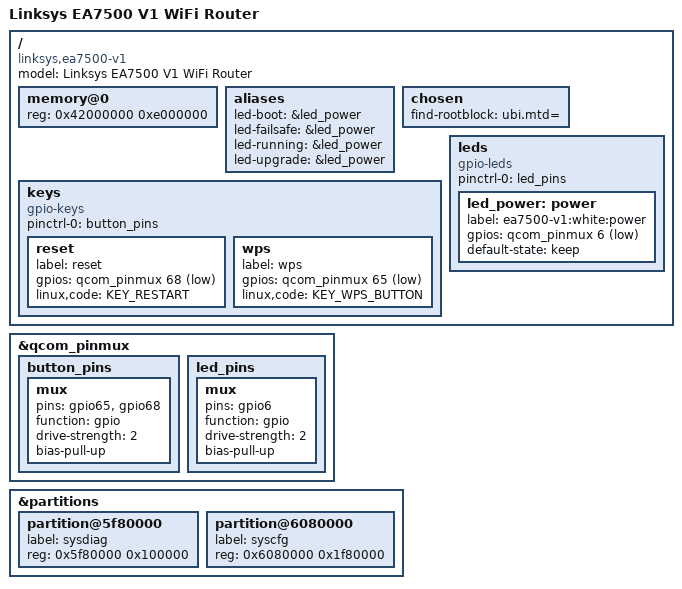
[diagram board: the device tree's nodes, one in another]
// SPDX-License-Identifier: GPL-2.0-or-later OR MIT

#include "qcom-ipq8064-eax500.dtsi"

/ {
	model = "Linksys EA7500 V1 WiFi Router";
	compatible = "linksys,ea7500-v1", "qcom,ipq8064";

	memory@0 {
		reg = <0x42000000 0xe000000>;
		device_type = "memory";
	};

	aliases {
		led-boot = &led_power;
		led-failsafe = &led_power;
		led-running = &led_power;
		led-upgrade = &led_power;
	};

	chosen {
		/* look for root deviceblock nbr in this bootarg */
		find-rootblock = "ubi.mtd=";
	};

	keys {
		compatible = "gpio-keys";
		pinctrl-0 = <&button_pins>;
		pinctrl-names = "default";

		reset {
			label = "reset";
			gpios = <&qcom_pinmux 68 GPIO_ACTIVE_LOW>;
			linux,code = <KEY_RESTART>;
		};

		wps {
			label = "wps";
			gpios = <&qcom_pinmux 65 GPIO_ACTIVE_LOW>;
			linux,code = <KEY_WPS_BUTTON>;
		};
	};

	leds {
		compatible = "gpio-leds";
		pinctrl-0 = <&led_pins>;
		pinctrl-names = "default";

		led_power: power {
			label = "ea7500-v1:white:power";
			gpios = <&qcom_pinmux 6 GPIO_ACTIVE_LOW>;
			default-state = "keep";
		};
	};
};

&qcom_pinmux {
	button_pins: button_pins {
		mux {
			pins = "gpio65", "gpio68";
			function = "gpio";
			drive-strength = <2>;
			bias-pull-up;
		};
	};

	led_pins: led_pins {
		mux {
			pins = "gpio6";
			function = "gpio";
			drive-strength = <2>;
			bias-pull-up;
		};
	};
};

&partitions {
	partition@5f80000 {
		label = "sysdiag";
		reg = <0x5f80000 0x100000>;
	};

	partition@6080000 {
		label = "syscfg";
		reg = <0x6080000 0x1f80000>;
	};
};
